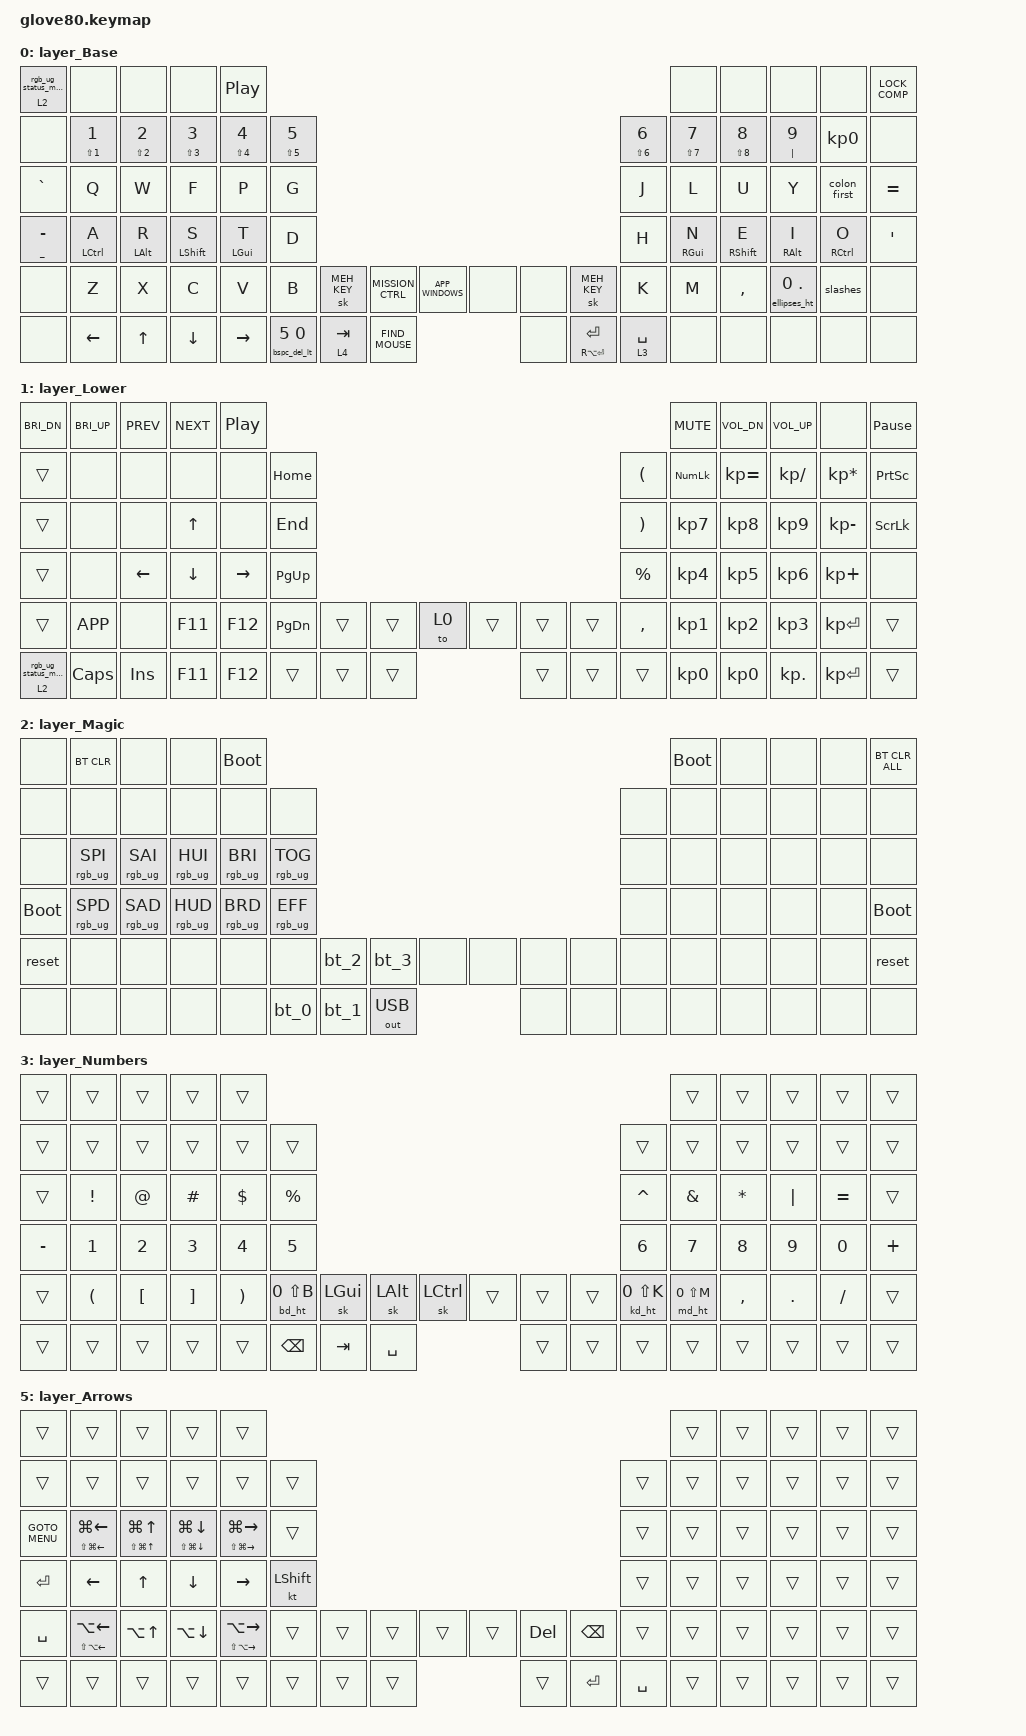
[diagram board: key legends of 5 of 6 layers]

/*
 * Copyright (c) 2020 The ZMK Contributors
 * Copyright (c) 2022 Innaworks Development Limited, trading as MoErgo
 *
 * SPDX-License-Identifier: MIT
 */


/* THIS FILE WAS GENERATED BY GLOVE80 LAYOUT EDITOR
 *
 * This file was generated automatically. You may or may not want to
 * edit it directly.
 */

#include <behaviors.dtsi>
/* Include all behaviour includes needed by system behaviors/macros */
#include <dt-bindings/zmk/outputs.h>

/* Include behaviour includes needed by key binds - automatically generated */
#include <dt-bindings/zmk/keys.h>
#include <dt-bindings/zmk/bt.h>
#include <dt-bindings/zmk/rgb.h>
#include <dt-bindings/zmk/outputs.h>


/ {
    /* Glove80 system behavior & macros */
    behaviors {
        // For the "layer" key, it'd nice to be able to use it as either a shift or a toggle.
        // Configure it as a tap dance, so the first tap (or hold) is a &mo and the second tap is a &to
        lower: tap_dance_0 {
            compatible = "zmk,behavior-tap-dance";
            label = "LAYER_TAP_DANCE";
            #binding-cells = <0>;
            tapping-term-ms = <200>;
            bindings = <&mo 1>, <&to 1>;
        };
    };

    macros {
        rgb_ug_status_macro: rgb_ug_status_macro_0 {
            label = "RGB_UG_STATUS";
            compatible = "zmk,behavior-macro";
            #binding-cells = <0>;
            bindings
                = <&rgb_ug RGB_STATUS>;
        };
    };

    macros {
        bt_0: bt_profile_macro_0 {
            label = "BT_0";
            compatible = "zmk,behavior-macro";
            #binding-cells = <0>;
            bindings
                = <&out OUT_BLE>,
                  <&bt BT_SEL 0>;
        };
    };

    macros {
        bt_1: bt_profile_macro_1 {
            label = "BT_1";
            compatible = "zmk,behavior-macro";
            #binding-cells = <0>;
            bindings
                = <&out OUT_BLE>,
                  <&bt BT_SEL 1>;
        };
    };

    macros {
        bt_2: bt_profile_macro_2 {
            label = "BT_2";
            compatible = "zmk,behavior-macro";
            #binding-cells = <0>;
            bindings
                = <&out OUT_BLE>,
                  <&bt BT_SEL 2>;
        };
    };

    macros {
        bt_3: bt_profile_macro_3 {
            label = "BT_3";
            compatible = "zmk,behavior-macro";
            #binding-cells = <0>;
            bindings
                = <&out OUT_BLE>,
                  <&bt BT_SEL 3>;
        };
    };

    magic: magic_hold_tap {
        compatible = "zmk,behavior-hold-tap";
        label = "MAGIC_HOLD_TAP";
        #binding-cells = <2>;
        flavor = "tap-preferred";
        tapping-term-ms = <200>;
        bindings = <&mo>, <&rgb_ug_status_macro>;
    };

    /* Custom Defined Behaviors */
#define COMBO_TERM_NORMAL 24
#define COMBO_TERM_SHORT  9
#define COMBO_TERM_LONG   51

#define HT_NORMAL 180
#define HT_LONG 250
#define HT_SHORT 130

#define MEH(key) LA(LC(LS(key)))
#define MEH_KEY  LA(LC(LEFT_SHIFT))

#define FIND_MOUSE MEH(F12)

#undef CUT
#undef COPY
#undef UNDO

#define CUT            LG(X)
#define COPY           LG(C)
#define PASTE          LG(V)
#define PLAIN_PASTE    LA(LS(PASTE)) // Plain Paste = paste a plain copy of the text
#define UNDO           LG(Z)
#define REDO           LS(UNDO)
#define SELECT_ALL     LG(A)
#define ALFRED         LG(SPACE)
#define CLIPBOARD_HIST LA(ALFRED)
#define SCREEN_CAPTURE LG(LS(N3))
#define INV_QUESTION   LA(LS(SLASH))  // ¿ ... ALT+?
#define LOCK_COMP      LG(LC(Q))
#define APP_SWITCH     LG(TAB)
#define NEXT_WINDOW    LG(GRAVE)
#define GOTO_MENU      LG(LS(GRAVE))
#define FULL_SCREEN    LG(LC(F))
#define ONE_PASSWORD   LG(LS(X))
#define APP_WINDOWS    LC(DOWN)
#define MISSION_CTRL   LC(UP)

#define COMBO(NAME, BINDINGS, KEYPOS, MS) \
    combo_##NAME { \
        bindings = <BINDINGS>; \
        key-positions = <KEYPOS>; \
        timeout-ms = <MS>; \
    };

#define MACRO_WAIT_TIME 30
#define ZMAC(name,...) \
    name: name { \
            label = ZMK_MACRO_STRINGIFY(ZM_ ## name); \
            compatible = "zmk,behavior-macro"; \
            #binding-cells = <0>; \
            wait-ms = <MACRO_WAIT_TIME>; \
            tap-ms = <MACRO_WAIT_TIME>; \
            bindings = __VA_ARGS__ ; \
        };

#define HT(code, name, tap_ms,...) \
    code: name { \
        compatible = "zmk,behavior-hold-tap"; \
        label = ZMK_MACRO_STRINGIFY(ZM_ ## name); \
        #binding-cells = <2>; \
        tapping-term-ms = <tap_ms>; \
        quick-tap-ms = <0>; \
        flavor = "balanced"; \
        bindings = __VA_ARGS__ ; \
    };

combos {
    compatible = "zmk,combos";

    // Left hand, upper row
    COMBO(esc           , &kp ESC           ,    24 25   , COMBO_TERM_NORMAL)
    COMBO(next_window   , &kp NEXT_WINDOW   ,    24    26, COMBO_TERM_NORMAL)
    COMBO(alfred        , &kp ALFRED        ,       25 26, COMBO_TERM_LONG  )
    COMBO(screen_capture, &kp SCREEN_CAPTURE, 23 24 25   , COMBO_TERM_LONG  )

    // Left hand, bottom row
    COMBO(undo       , &kp UNDO       , 47 48      , COMBO_TERM_LONG)
    COMBO(redo       , &kp REDO       , 47 48 49   , COMBO_TERM_LONG)
    COMBO(cut        , &kp CUT        , 47    49   , COMBO_TERM_LONG)
    COMBO(copy       , &kp COPY       ,    48 49   , COMBO_TERM_LONG)
    COMBO(paste      , &kp PASTE      ,       49 50, COMBO_TERM_LONG)
    COMBO(plain_paste, &kp PLAIN_PASTE,    48 49 50, COMBO_TERM_LONG)
    COMBO(select_all , &kp SELECT_ALL , 47       50, COMBO_TERM_LONG)
    COMBO(app_switch , &kp APP_SWITCH ,    48    50, COMBO_TERM_LONG)

    // Left hand, other
    COMBO(cmd_t         , &kp LG(T)               ,             38 39               , COMBO_TERM_NORMAL)
    COMBO(cmd_p         , &kp LG(P)               ,    26 36                        , COMBO_TERM_NORMAL)
    COMBO(cmd_shift_p   , &kp LG(LS(P))           , 25 26 36                        , COMBO_TERM_NORMAL)
    COMBO(cmd_b         , &kp LG(B)               ,             38                51, COMBO_TERM_NORMAL)
    COMBO(clipboard_hist, &kp CLIPBOARD_HIST      ,       36                49 50   , COMBO_TERM_LONG  )
    COMBO(one_pw        , &kp ONE_PASSWORD        ,          37 38       48         , COMBO_TERM_LONG  )
    COMBO(grave         , &triple_grave_ht 0 GRAVE,          37       47            , COMBO_TERM_LONG  )
    COMBO(tilde         , &kp TILDE               ,       36          47            , COMBO_TERM_LONG  )

    // Right hand, upper row
    COMBO(quote   , &double_quote_ht 0 DOUBLE_QUOTES, 29 30   , COMBO_TERM_NORMAL)
    COMBO(plus    , &kp PLUS                        , 29    31, COMBO_TERM_NORMAL)
    COMBO(capsword, &caps_word                      ,    30 31, COMBO_TERM_NORMAL)

    // Right hand, bottom row
    COMBO(sticky_shift, &skqr RIGHT_SHIFT            ,    60 61   , COMBO_TERM_LONG  )
    COMBO(inv_question, &questions_ht 0 INV_QUESTION , 59 60      , COMBO_TERM_LONG  )
    COMBO(question    , &kp QUESTION                 ,       61 62, COMBO_TERM_LONG  )
    COMBO(colon       , &kp COLON                    , 59    61   , COMBO_TERM_NORMAL)
    COMBO(left_brace  , &kp LBRC                     , 59 60 61   , COMBO_TERM_LONG  )
    COMBO(right_brace , &kp RBRC                     ,    60 61 62, COMBO_TERM_LONG  )
    COMBO(lte_combo   , &lte_ht 0 LT                 , 59 60    62, COMBO_TERM_LONG  )
    COMBO(gte_combo   , &gte_ht 0 GT                 , 59    61 62, COMBO_TERM_LONG  )

    // Right hand, other
    COMBO(cmd_n    , &kp RG(N)    ,       40 41            , COMBO_TERM_NORMAL)
    COMBO(cmd_l    , &kp RG(L)    , 29             43      , COMBO_TERM_NORMAL)
    COMBO(equal    , &kp EQUAL    ,    30             44   , COMBO_TERM_SHORT )
    COMBO(semicolon, &kp SEMICOLON,             42       62, COMBO_TERM_NORMAL)
};

macros {
    ZMAC(triple_grave, <&kp GRAVE &kp GRAVE &kp GRAVE>)
    ZMAC(ellipses    , <&kp DOT &kp DOT &kp DOT>      )
    
    ZMAC(lte, <&kp LT &kp EQUAL>)
    ZMAC(gte, <&kp GT &kp EQUAL>)
    
    ZMAC(m_dollars, <&kp M &kp D &kp SLASH>)
    ZMAC(k_dollars, <&kp K &kp D &kp SLASH>)
    ZMAC(b_dollars, <&kp B &kp D &kp SLASH>)

    ZMAC(question_marks, <&kp INV_QUESTION &kp QUESTION &kp LEFT>      )
    ZMAC(double_quotes , <&kp DOUBLE_QUOTES &kp DOUBLE_QUOTES &kp LEFT>)
};

behaviors {
    HT(as             , auto_shift              , HT_NORMAL, <&kp &kp>            )
    HT(as_long        , auto_shift_long         , HT_LONG  , <&kp &kp>            )
    HT(as_short       , auto_shift_short        , HT_SHORT , <&kp &kp>            )
    HT(hrm            , homerow_mods            , HT_NORMAL, <&kp &kp>            )
    HT(bd_ht          , billion_dollar_hold_tap , HT_NORMAL, <&b_dollars &kp>     )
    HT(md_ht          , million_dollar_hold_tap , HT_NORMAL, <&m_dollars &kp>     )
    HT(kd_ht          , thousand_dollar_hold_tap, HT_NORMAL, <&k_dollars &kp>     )
    HT(triple_grave_ht, triple_grave_hold_tap   , HT_NORMAL, <&triple_grave &kp>  )
    HT(ellipses_ht    , ellipses_hold_tap       , HT_NORMAL, <&ellipses &kp>      )
    HT(bspc_del_lt    , bspc_del_layer_tap      , HT_NORMAL, <&mo &bspc_del>      )
    HT(lte_ht         , less_than_hold_tap      , HT_NORMAL, <&lte &kp>           )
    HT(gte_ht         , greater_than_hold_tap   , HT_NORMAL, <&gte &kp>           )
    HT(questions_ht   , question_marks_hold_tap , HT_NORMAL, <&question_marks &kp>)
    HT(double_quote_ht, double_quotes_hold_tap  , HT_NORMAL, <&double_quotes &kp> )

    bspc_del: backspace_delete {
        compatible = "zmk,behavior-mod-morph";
        label = "BACKSPACE_DELETE";
        #binding-cells = <0>;
        bindings = <&kp BACKSPACE>, <&kp DELETE>;
        mods = <(MOD_LSFT|MOD_RSFT)>;
    };

    skqr: sticky_key_quick_release {
        compatible = "zmk,behavior-sticky-key";
        label = "STICKY_KEY_QUICK_RELEASE";
        #binding-cells = <1>;
        bindings = <&kp>;
        release-after-ms = <1000>;
        quick-release;
        ignore-modifiers;
    };

    slashes: slashes {
        compatible = "zmk,behavior-mod-morph";
        label = "SLASHES";
        #binding-cells = <0>;
        bindings = <&kp SLASH>, <&kp BACKSLASH>;
        mods = <(MOD_LSFT|MOD_RSFT)>;
    };

    colon_first: colon_first {
        compatible = "zmk,behavior-mod-morph";
        label = "COLON_FIRST";
        #binding-cells = <0>;
        bindings = <&kp COLON>, <&kp SEMICOLON>;
        mods = <(MOD_LSFT|MOD_RSFT)>;
    };
};

    /* Automatically generated keymap */
    keymap {
        compatible = "zmk,keymap";


        layer_Base {
            bindings = <
            &magic 2 0          &none          &none          &none       &kp C_PP                                                                                                                                            &none          &none               &none         &none  &kp LOCK_COMP
                 &none  &as LS(N1) N1  &as LS(N2) N2  &as LS(N3) N3  &as LS(N4) N4  &as LS(N5) N5                                                                                                      &as LS(N6) N6  &as LS(N7) N7  &as LS(N8) N8         &as PIPE N9     &kp KP_N0          &none
             &kp GRAVE          &kp Q          &kp W          &kp F          &kp P          &kp G                                                                                                              &kp J          &kp L          &kp U               &kp Y  &colon_first      &kp EQUAL
 &as_short UNDER MINUS    &hrm LCTL A    &hrm LALT R  &hrm LSHIFT S    &hrm LGUI T          &kp D                                                                                                              &kp H    &hrm RGUI N  &hrm RSHIFT E         &hrm RALT I   &hrm RCTL O        &kp SQT
                 &none          &kp Z          &kp X          &kp C          &kp V          &kp B       &sk MEH_KEY  &kp MISSION_CTRL  &kp APP_WINDOWS   &none                     &none  &sk MEH_KEY          &kp K          &kp M      &kp COMMA  &ellipses_ht 0 DOT      &slashes          &none
                 &none       &kp LEFT         &kp UP       &kp DOWN      &kp RIGHT                 &bspc_del_lt 5 0         &lt 4 TAB   &kp FIND_MOUSE   &none  &as_long RA(ENTER) ENTER  &lt 3 SPACE                         &none          &none               &none         &none          &none
            >;
        };

        layer_Lower {
            bindings = <
 &kp C_BRI_DN  &kp C_BRI_UP      &kp C_PREV      &kp C_NEXT         &kp C_PP                                                                                    &kp C_MUTE  &kp C_VOL_DN  &kp C_VOL_UP            &none  &kp PAUSE_BREAK
       &trans         &none           &none           &none            &none   &kp HOME                                                   &kp LEFT_PARENTHESIS  &kp KP_NUM  &kp KP_EQUAL  &kp KP_SLASH  &kp KP_MULTIPLY  &kp PRINTSCREEN
       &trans         &none           &none    &kp UP_ARROW            &none    &kp END                                                  &kp RIGHT_PARENTHESIS   &kp KP_N7     &kp KP_N8     &kp KP_N9     &kp KP_MINUS   &kp SCROLLLOCK
       &trans         &none  &kp LEFT_ARROW  &kp DOWN_ARROW  &kp RIGHT_ARROW  &kp PG_UP                                                            &kp PERCENT   &kp KP_N4     &kp KP_N5     &kp KP_N6      &kp KP_PLUS            &none
       &trans     &kp K_APP           &none         &kp F11          &kp F12  &kp PG_DN  &trans  &trans   &to 0  &trans  &trans  &trans              &kp COMMA   &kp KP_N1     &kp KP_N2     &kp KP_N3     &kp KP_ENTER           &trans
   &magic 2 0      &kp CAPS         &kp INS         &kp F11          &kp F12             &trans  &trans  &trans  &trans  &trans  &trans                          &kp KP_N0     &kp KP_N0    &kp KP_DOT     &kp KP_ENTER           &trans
            >;
        };

        layer_Magic {
            bindings = <
       &none       &bt BT_CLR            &none            &none      &bootloader                                                                                 &bootloader   &none   &none   &none  &bt BT_CLR_ALL
       &none            &none            &none            &none            &none            &none                                                         &none        &none   &none   &none   &none           &none
       &none  &rgb_ug RGB_SPI  &rgb_ug RGB_SAI  &rgb_ug RGB_HUI  &rgb_ug RGB_BRI  &rgb_ug RGB_TOG                                                         &none        &none   &none   &none   &none           &none
 &bootloader  &rgb_ug RGB_SPD  &rgb_ug RGB_SAD  &rgb_ug RGB_HUD  &rgb_ug RGB_BRD  &rgb_ug RGB_EFF                                                         &none        &none   &none   &none   &none     &bootloader
      &reset            &none            &none            &none            &none            &none   &bt_2   &bt_3         &none   &none   &none   &none   &none        &none   &none   &none   &none          &reset
       &none            &none            &none            &none            &none                    &bt_0   &bt_1  &out OUT_USB   &none   &none   &none                &none   &none   &none   &none           &none
            >;
        };

        layer_Numbers {
            bindings = <
    &trans    &trans    &trans    &trans    &trans                                                                                                 &trans     &trans    &trans     &trans    &trans
    &trans    &trans    &trans    &trans    &trans          &trans                                                                 &trans          &trans     &trans    &trans     &trans    &trans
    &trans  &kp EXCL    &kp AT  &kp HASH  &kp DLLR       &kp PRCNT                                                              &kp CARET        &kp AMPS   &kp STAR  &kp PIPE  &kp EQUAL    &trans
 &kp MINUS    &kp N1    &kp N2    &kp N3    &kp N4          &kp N5                                                                 &kp N6          &kp N7     &kp N8    &kp N9     &kp N0  &kp PLUS
    &trans  &kp LPAR  &kp LBKT  &kp RBKT  &kp RPAR  &bd_ht 0 LS(B)  &sk LGUI  &sk LALT  &sk LCTRL  &trans  &trans  &trans  &kd_ht 0 LS(K)  &md_ht 0 LS(M)  &kp COMMA   &kp DOT   &kp FSLH    &trans
    &trans    &trans    &trans    &trans    &trans                  &kp BSPC   &kp TAB  &kp SPACE  &trans  &trans  &trans                          &trans     &trans    &trans     &trans    &trans
            >;
        };

        layer_Window_Mgmt {
            bindings = <
 &trans       &trans       &trans                   &trans       &trans                                                                           &trans  &trans  &trans  &trans  &trans
 &trans       &trans       &trans                   &trans       &trans           &trans                                                  &trans  &trans  &trans  &trans  &trans  &trans
 &trans  &kp MEH(N0)  &kp MEH(N7)              &kp MEH(N8)  &kp MEH(N9)  &kp MEH(PERIOD)                                                  &trans  &trans  &trans  &trans  &trans  &trans
 &trans  &kp MEH(N0)  &kp MEH(N4)  &as FULL_SCREEN MEH(N5)  &kp MEH(N6)  &kp MEH(PERIOD)                                                  &trans  &trans  &trans  &trans  &trans  &trans
 &trans  &kp MEH(N0)  &kp MEH(N1)              &kp MEH(N2)  &kp MEH(N3)  &kp MEH(PERIOD)  &trans  &trans  &trans  &trans  &trans  &trans  &trans  &trans  &trans  &trans  &trans  &trans
 &trans       &trans       &trans                   &trans       &trans                   &trans  &trans  &trans  &trans  &trans  &trans          &trans  &trans  &trans  &trans  &trans
            >;
        };

        layer_Arrows {
            bindings = <
        &trans                     &trans                 &trans                     &trans                       &trans                                                                         &trans  &trans  &trans  &trans  &trans
        &trans                     &trans                 &trans                     &trans                       &trans     &trans                                                      &trans  &trans  &trans  &trans  &trans  &trans
 &kp GOTO_MENU  &as LS(LG(LEFT)) LG(LEFT)  &as LS(LG(UP)) LG(UP)  &as LS(LG(DOWN)) LG(DOWN)  &as LS(LG(RIGHT)) LG(RIGHT)     &trans                                                      &trans  &trans  &trans  &trans  &trans  &trans
       &kp RET                   &kp LEFT                 &kp UP                   &kp DOWN                    &kp RIGHT  &kt LSHFT                                                      &trans  &trans  &trans  &trans  &trans  &trans
     &kp SPACE  &as LS(LA(LEFT)) LA(LEFT)             &kp LA(UP)               &kp LA(DOWN)  &as LS(LA(RIGHT)) LA(RIGHT)     &trans  &trans  &trans  &trans  &trans  &kp DEL   &kp BSPC  &trans  &trans  &trans  &trans  &trans  &trans
        &trans                     &trans                 &trans                     &trans                       &trans             &trans  &trans  &trans  &trans  &kp RET  &kp SPACE          &trans  &trans  &trans  &trans  &trans
            >;
        };

    };
};
